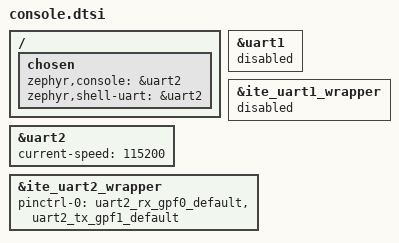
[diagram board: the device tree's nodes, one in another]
/* Copyright 2024 The ChromiumOS Authors
 * Use of this source code is governed by a BSD-style license that can be
 * found in the LICENSE file.
 */

/ {
	chosen {
		zephyr,console = &uart2;
		zephyr,shell-uart = &uart2;
	};
};

/* UART interface is SIN1/SOUT1 pins, which ITE maps to devicetree uart2 */
&uart1 {
	status = "disabled";
};

&ite_uart1_wrapper {
	status = "disabled";
};

&uart2 {
	status = "okay";
	current-speed = <115200>;
};

&ite_uart2_wrapper {
	status = "okay";
	pinctrl-0 = <&uart2_rx_gpf0_default
		     &uart2_tx_gpf1_default>;
	pinctrl-names = "default";
};
